CM_ "AUTOGENERATED FILE, DO NOT EDIT"

CM_ "toyota_auris_2014_pt.dbc starts here"
VERSION ""

NS_ :

BS_:

BU_: XXX DSU HCU EPS IPAS CGW SCM

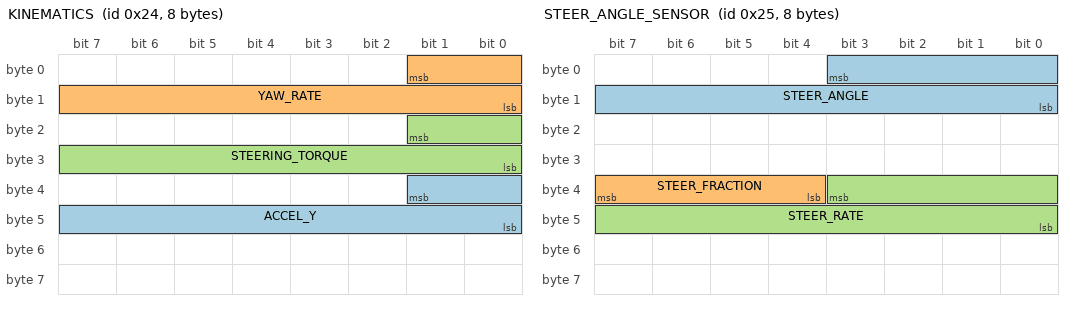
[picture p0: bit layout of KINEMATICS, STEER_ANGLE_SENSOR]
BO_ 36 KINEMATICS: 8 XXX
 SG_ ACCEL_Y : 33|10@0+ (0.03589,-18.375) [0|65535] "m/s^2" XXX
 SG_ YAW_RATE : 1|10@0+ (0.244,-125) [0|65535] "deg/sec" XXX
 SG_ STEERING_TORQUE : 17|10@0+ (1,-512) [0|65535] "" XXX

BO_ 37 STEER_ANGLE_SENSOR: 8 XXX
 SG_ STEER_ANGLE : 3|12@0- (1.5,0) [-500|500] "deg" XXX
 SG_ STEER_FRACTION : 39|4@0- (0.1,0) [-0.7|0.7] "deg" XXX
 SG_ STEER_RATE : 35|12@0- (1,0) [-2000|2000] "deg/s" XXX

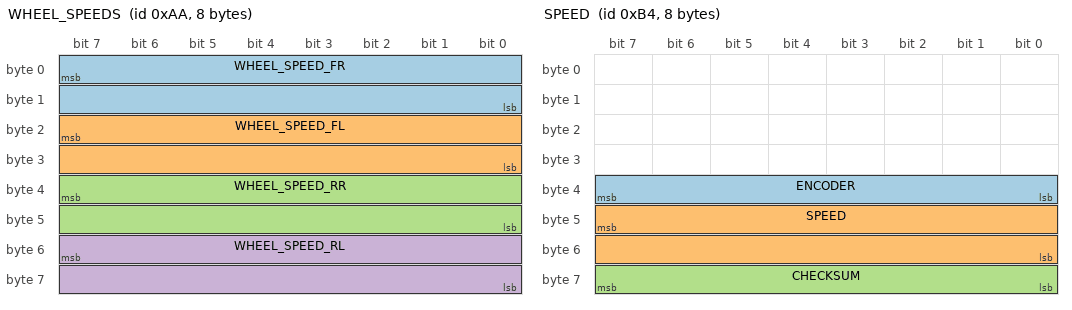
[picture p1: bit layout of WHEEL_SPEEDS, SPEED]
BO_ 170 WHEEL_SPEEDS: 8 XXX
 SG_ WHEEL_SPEED_FR : 7|16@0+ (0.01,-67.67) [0|250] "kph" XXX
 SG_ WHEEL_SPEED_FL : 23|16@0+ (0.01,-67.67) [0|250] "kph" XXX
 SG_ WHEEL_SPEED_RR : 39|16@0+ (0.01,-67.67) [0|250] "kph" XXX
 SG_ WHEEL_SPEED_RL : 55|16@0+ (0.01,-67.67) [0|250] "kph" XXX

BO_ 180 SPEED: 8 XXX
 SG_ ENCODER : 39|8@0+ (1,0) [0|255] "" XXX
 SG_ SPEED : 47|16@0+ (0.01,0) [0|250] "kph" XXX
 SG_ CHECKSUM : 63|8@0+ (1,0) [0|255] "" XXX

BO_ 548 BRAKE: 8 XXX
 SG_ BRAKE_PRESSED : 5|1@0+ (1,0) [0|1] "" XXX
 SG_ BRAKE_AMOUNT : 47|8@0+ (1,0) [0|255] "" XXX

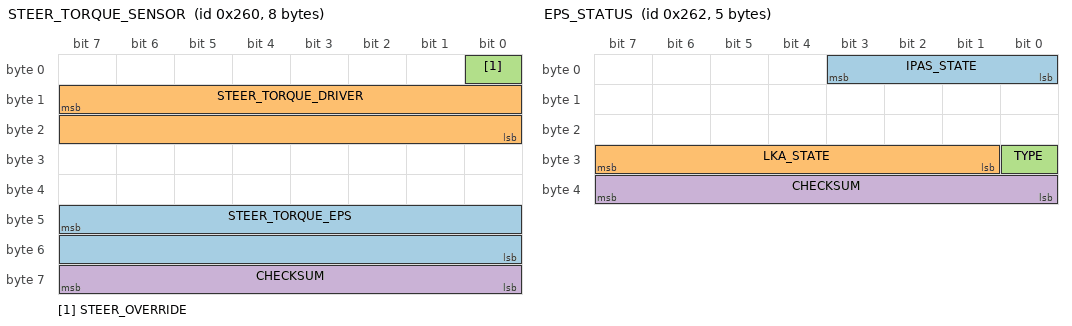
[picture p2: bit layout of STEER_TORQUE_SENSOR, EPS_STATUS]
BO_ 608 STEER_TORQUE_SENSOR: 8 XXX
 SG_ STEER_TORQUE_EPS : 47|16@0- (1.0,0) [-20000|20000] "" XXX
 SG_ STEER_TORQUE_DRIVER : 15|16@0- (1,0) [-32768|32767] "" XXX
 SG_ STEER_OVERRIDE : 0|1@0+ (1,0) [0|1] "" XXX
 SG_ CHECKSUM : 63|8@0+ (1,0) [0|255] "" XXX

BO_ 610 EPS_STATUS: 5 EPS
 SG_ IPAS_STATE : 3|4@0+ (1,0) [0|15] "" XXX
 SG_ LKA_STATE : 31|7@0+ (1,0) [0|127] "" XXX
 SG_ TYPE : 24|1@0+ (1,0) [0|1] "" XXX
 SG_ CHECKSUM : 39|8@0+ (1,0) [0|255] "" XXX

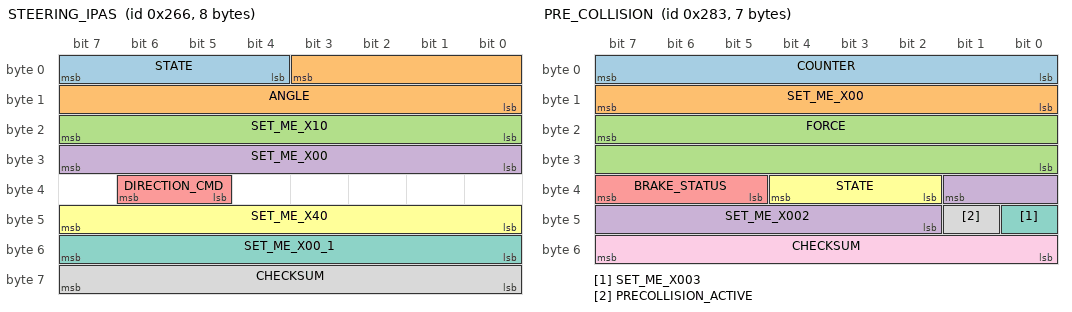
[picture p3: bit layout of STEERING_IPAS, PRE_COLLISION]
BO_ 614 STEERING_IPAS: 8 IPAS
 SG_ STATE : 7|4@0+ (1,0) [0|15] "" XXX
 SG_ ANGLE : 3|12@0- (1.5,0) [-510|510] "deg" XXX
 SG_ SET_ME_X10 : 23|8@0+ (1,0) [0|255] "" XXX
 SG_ SET_ME_X00 : 31|8@0+ (1,0) [0|255] "" XXX
 SG_ DIRECTION_CMD : 38|2@0+ (1,0) [0|3] "" XXX
 SG_ SET_ME_X40 : 47|8@0+ (1,0) [0|255] "" XXX
 SG_ SET_ME_X00_1 : 55|8@0+ (1,0) [0|255] "" XXX
 SG_ CHECKSUM : 63|8@0+ (1,0) [0|255] "" XXX

BO_ 643 PRE_COLLISION: 7 DSU
 SG_ COUNTER : 7|8@0+ (1,0) [0|255] "" XXX
 SG_ SET_ME_X00 : 15|8@0+ (1,0) [0|255] "" XXX
 SG_ FORCE : 23|16@0- (2,0) [0|255] "N" XXX
 SG_ SET_ME_X002 : 33|8@0+ (1,0) [0|3] "" XXX
 SG_ BRAKE_STATUS : 39|3@0+ (1,0) [0|255] "" XXX
 SG_ STATE : 36|3@0+ (1,0) [0|255] "" XXX
 SG_ SET_ME_X003 : 40|1@0+ (1,0) [0|1] "" XXX
 SG_ PRECOLLISION_ACTIVE : 41|1@0+ (1,0) [0|255] "" XXX
 SG_ CHECKSUM : 55|8@0+ (1,0) [0|255] "" XXX

BO_ 836 PRE_COLLISION_2: 8 DSU
 SG_ CHECKSUM : 63|8@0+ (1,0) [0|0] "" XXX

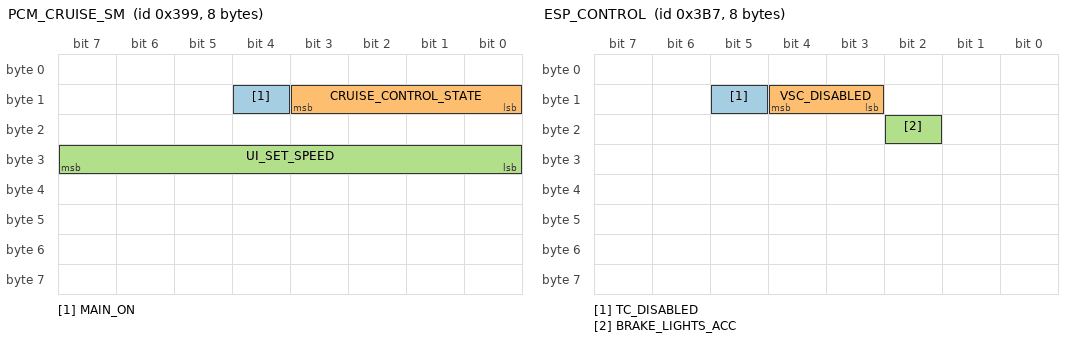
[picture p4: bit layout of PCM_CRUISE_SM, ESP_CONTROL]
BO_ 921 PCM_CRUISE_SM: 8 XXX
 SG_ MAIN_ON : 12|1@0+ (1,0) [0|1] "" XXX
 SG_ CRUISE_CONTROL_STATE : 11|4@0+ (1,0) [0|15] "" XXX
 SG_ UI_SET_SPEED : 31|8@0+ (1,0) [0|255] "" XXX

BO_ 951 ESP_CONTROL: 8 ESP
 SG_ TC_DISABLED : 13|1@0+ (1,0) [0|1] "" XXX
 SG_ VSC_DISABLED : 12|2@0+ (1,0) [0|1] "" XXX
 SG_ BRAKE_LIGHTS_ACC : 18|1@0+ (1,0) [0|1] "" XXX

BO_ 956 GEAR_PACKET: 8 XXX
 SG_ GEAR : 13|6@0+ (1,0) [0|63] "" XXX
 SG_ SPORT_ON : 3|1@0+ (1,0) [0|1] "" XXX

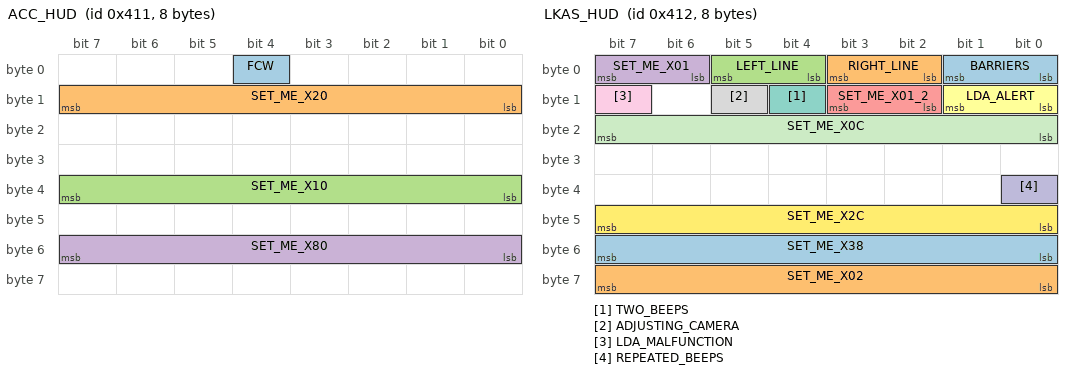
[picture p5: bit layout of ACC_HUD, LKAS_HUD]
BO_ 1041 ACC_HUD: 8 DSU
 SG_ FCW : 4|1@0+ (1,0) [0|1] "" XXX
 SG_ SET_ME_X20 : 15|8@0+ (1,0) [0|1] "" XXX
 SG_ SET_ME_X10 : 39|8@0+ (1,0) [0|1] "" XXX
 SG_ SET_ME_X80 : 55|8@0+ (1,0) [0|1] "" XXX

BO_ 1042 LKAS_HUD: 8 XXX
 SG_ BARRIERS : 1|2@0+ (1,0) [0|3] "" XXX
 SG_ RIGHT_LINE : 3|2@0+ (1,0) [0|3] "" XXX
 SG_ LEFT_LINE : 5|2@0+ (1,0) [0|3] "" XXX
 SG_ SET_ME_X01 : 7|2@0+ (1,0) [0|3] "" XXX
 SG_ SET_ME_X01_2 : 11|2@0+ (1,0) [0|3] "" XXX
 SG_ LDA_ALERT : 9|2@0+ (1,0) [0|3] "" XXX
 SG_ TWO_BEEPS : 12|1@0+ (1,0) [0|1] "" XXX
 SG_ ADJUSTING_CAMERA : 13|1@0+ (1,0) [0|1] "" XXX
 SG_ LDA_MALFUNCTION : 15|1@0+ (1,0) [0|1] "" XXX
 SG_ REPEATED_BEEPS : 32|1@0+ (1,0) [0|1] "" XXX
 SG_ SET_ME_X0C : 23|8@0+ (1,0) [0|1] "" XXX
 SG_ SET_ME_X2C : 47|8@0+ (1,0) [0|1] "" XXX
 SG_ SET_ME_X38 : 55|8@0+ (1,0) [0|1] "" XXX
 SG_ SET_ME_X02 : 63|8@0+ (1,0) [0|1] "" XXX

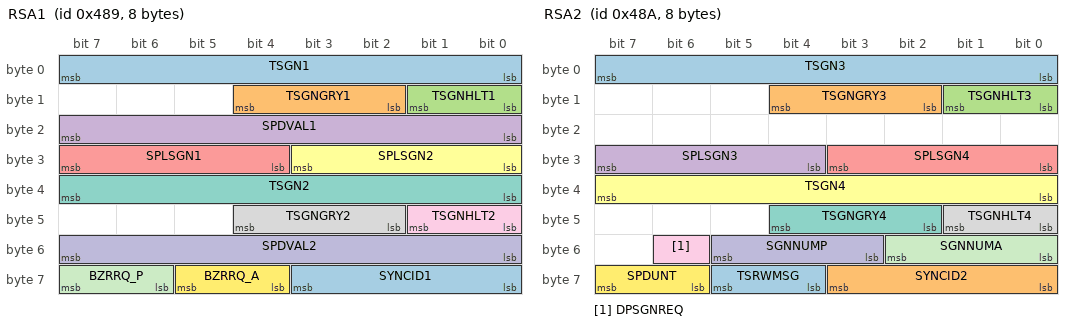
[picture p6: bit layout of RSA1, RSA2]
BO_ 1161 RSA1: 8 FCM
 SG_ TSGN1 : 7|8@0+ (1,0) [0|0] "" XXX
 SG_ TSGNGRY1 : 12|3@0+ (1,0) [0|0] "" XXX
 SG_ TSGNHLT1 : 9|2@0+ (1,0) [0|0] "" XXX
 SG_ SPDVAL1 : 23|8@0+ (1,0) [0|0] "kph" XXX
 SG_ SPLSGN1 : 31|4@0+ (1,0) [0|0] "" XXX
 SG_ SPLSGN2 : 27|4@0+ (1,0) [0|0] "" XXX
 SG_ TSGN2 : 39|8@0+ (1,0) [0|0] "" XXX
 SG_ TSGNGRY2 : 44|3@0+ (1,0) [0|0] "" XXX
 SG_ TSGNHLT2 : 41|2@0+ (1,0) [0|0] "" XXX
 SG_ SPDVAL2 : 55|8@0+ (1,0) [0|0] "" XXX
 SG_ BZRRQ_P : 63|2@0+ (1,0) [0|0] "" XXX
 SG_ BZRRQ_A : 61|2@0+ (1,0) [0|0] "" XXX
 SG_ SYNCID1 : 59|4@0+ (1,0) [0|0] "" XXX

BO_ 1162 RSA2: 8 FCM
 SG_ TSGN3 : 7|8@0+ (1,0) [0|0] "" XXX
 SG_ TSGNGRY3 : 12|3@0+ (1,0) [0|0] "" XXX
 SG_ TSGNHLT3 : 9|2@0+ (1,0) [0|0] "" XXX
 SG_ SPLSGN3 : 31|4@0+ (1,0) [0|0] "" XXX
 SG_ SPLSGN4 : 27|4@0+ (1,0) [0|0] "" XXX
 SG_ TSGN4 : 39|8@0+ (1,0) [0|0] "" XXX
 SG_ TSGNGRY4 : 44|3@0+ (1,0) [0|0] "" XXX
 SG_ TSGNHLT4 : 41|2@0+ (1,0) [0|0] "" XXX
 SG_ DPSGNREQ : 54|1@0+ (1,0) [0|0] "" XXX
 SG_ SGNNUMP : 53|3@0+ (1,0) [0|0] "" XXX
 SG_ SGNNUMA : 50|3@0+ (1,0) [0|0] "" XXX
 SG_ SPDUNT : 63|2@0+ (1,0) [0|0] "" XXX
 SG_ TSRWMSG : 61|2@0+ (1,0) [0|0] "" XXX
 SG_ SYNCID2 : 59|4@0+ (1,0) [0|0] "" XXX

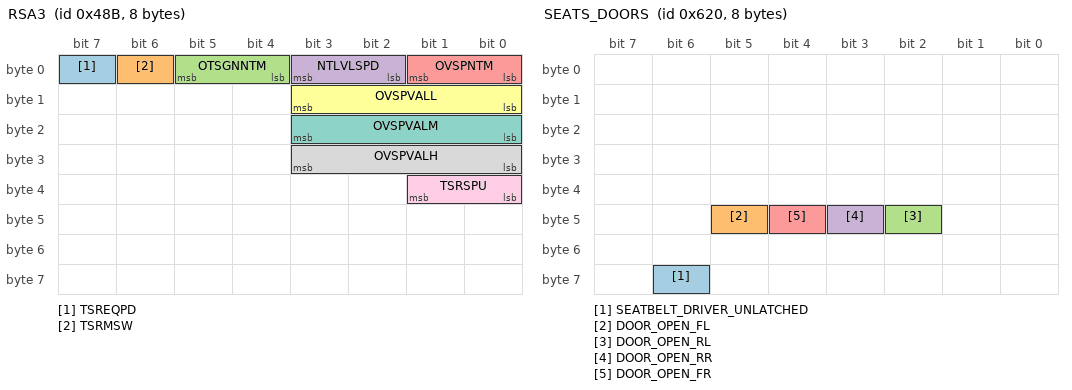
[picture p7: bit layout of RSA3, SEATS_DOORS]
BO_ 1163 RSA3: 8 FCM
 SG_ TSREQPD : 7|1@0+ (1,0) [0|0] "" XXX
 SG_ TSRMSW : 6|1@0+ (1,0) [0|0] "" XXX
 SG_ OTSGNNTM : 5|2@0+ (1,0) [0|0] "" XXX
 SG_ NTLVLSPD : 3|2@0+ (1,0) [0|0] "" XXX
 SG_ OVSPNTM : 1|2@0+ (1,0) [0|0] "" XXX
 SG_ OVSPVALL : 11|4@0+ (1,-5) [0|0] "" XXX
 SG_ OVSPVALM : 19|4@0+ (1,-5) [0|0] "" XXX
 SG_ OVSPVALH : 27|4@0+ (1,-5) [0|0] "" XXX
 SG_ TSRSPU : 33|2@0+ (1,0) [0|0] "" XXX

BO_ 1553 UI_SETTING: 8 XXX
 SG_ UNITS : 26|2@0+ (1,0) [0|3] "" XXX

BO_ 1556 STEERING_LEVERS: 8 XXX
 SG_ TURN_SIGNALS : 29|2@0+ (1,0) [0|3] "" XXX

BO_ 1568 SEATS_DOORS: 8 XXX
 SG_ SEATBELT_DRIVER_UNLATCHED : 62|1@0+ (1,0) [0|1] "" XXX
 SG_ DOOR_OPEN_FL : 45|1@0+ (1,0) [0|1] "" XXX
 SG_ DOOR_OPEN_RL : 42|1@0+ (1,0) [0|1] "" XXX
 SG_ DOOR_OPEN_RR : 43|1@0+ (1,0) [0|1] "" XXX
 SG_ DOOR_OPEN_FR : 44|1@0+ (1,0) [0|1] "" XXX

BO_ 1570 LIGHT_STALK: 8 SCM
 SG_ AUTO_HIGH_BEAM : 37|1@0+ (1,0) [0|1] "" XXX

CM_ SG_ 36 ACCEL_Y "does not seems to be Y accel, TBD";
CM_ SG_ 36 YAW_RATE "seems true";
CM_ SG_ 36 STEERING_TORQUE "definitely not the steering torque, TBD";
CM_ SG_ 37 STEER_ANGLE "positive is left, negative is right";
CM_ SG_ 37 STEER_FRACTION "1/15th of the signal STEER_ANGLE, which is 1.5 deg; note that 0x8 is never set";
CM_ SG_ 37 STEER_RATE "factor is tbd";
CM_ SG_ 608 STEER_TORQUE_DRIVER "driver torque";
CM_ SG_ 608 STEER_OVERRIDE "set when driver torque exceeds a certain value";
CM_ SG_ 610 LKA_STATE "0 value, not in range, TBD";
CM_ SG_ 610 TYPE "seems 1 on Corolla, 0 on all others";
CM_ SG_ 614 ANGLE "set to measured angle when ipas control isn't active";
CM_ SG_ 643 COUNTER "only used on cars that use this msg for cruise control";
CM_ SG_ 643 BRAKE_STATUS "only used on cars that use this msg for cruise control";
CM_ SG_ 643 PRECOLLISION_ACTIVE "set 0.5s before any braking";
CM_ SG_ 921 UI_SET_SPEED "set speed shown in UI with user set unit";
CM_ SG_ 951 BRAKE_LIGHTS_ACC "brake lights when ACC commands decel";
CM_ SG_ 1042 SET_ME_1 "unclear what this is, but it's always 1 in drive traces";
CM_ SG_ 1042 REPEATED_BEEPS "recommended for fcw and other important alerts";
CM_ SG_ 1161 SPDVAL1 "Numbers 0-199 is displayed, 200-254 displays circle without number and 255 is for no limit.";
CM_ SG_ 1161 SYNCID1 "counter from 1 to f at 1 Hz";
CM_ SG_ 1161 SPDVAL2 "conditional speed value 70"
CM_ SG_ 1162 SGNNUMP "1 if SPDVAL1 is set, otherwise 0";
CM_ SG_ 1162 SYNCID2 "counter from 1 to f at 1 Hz";
CM_ SG_ 1163 TSREQPD "always 1";
CM_ SG_ 1163 TSRMSW "always 1";
CM_ SG_ 1163 OTSGNNTM "always 3";
CM_ SG_ 1163 NTLVLSPD "always 3";
CM_ SG_ 1163 OVSPNTM "always 3";
CM_ SG_ 1163 OVSPVALL "-5 at start then 2 after 2 seconds";
CM_ SG_ 1163 OVSPVALM "-5 at start then 5 after 2 seconds";
CM_ SG_ 1163 OVSPVALH "-5 at start then 10 after 2 seconds";
CM_ SG_ 1163 TSRSPU "always 1";

VAL_ 548 BRAKE_PRESSED 0 "not pressed" 1 "pressed";
VAL_ 610 IPAS_STATE 5 "override" 3 "enabled" 1 "disabled";
VAL_ 610 LKA_STATE 25 "temporary_fault" 9 "temporary_fault2" 5 "active" 1 "standby";
VAL_ 614 STATE 3 "enabled" 1 "disabled";
VAL_ 614 DIRECTION_CMD 3 "right" 2 "center" 1 "left";
VAL_ 643 STATE 0 "normal" 1 "adaptive_cruise_control" 3 "emergency_braking";
VAL_ 921 CRUISE_CONTROL_STATE 0 "disabled" 2 "enabled";
VAL_ 956 GEAR 0 "D" 1 "S" 8 "N" 16 "R" 32 "P";
VAL_ 1042 LDA_ALERT 3 "hold with continuous beep" 2 "LDA unavailable" 1 "hold" 0 "none";
VAL_ 1042 BARRIERS 3 "both" 2 "right" 1 "left" 0 "none";
VAL_ 1042 RIGHT_LINE 3 "orange" 2 "faded" 1 "solid" 0 "none";
VAL_ 1042 LEFT_LINE 3 "orange" 2 "faded" 1 "solid" 0 "none";
VAL_ 1553 UNITS 1 "km" 2 "miles";
VAL_ 1556 TURN_SIGNALS 3 "none" 2 "right" 1 "left";
VAL_ 1161 TSGN1 1 "speed sign" 0 "none";
VAL_ 1161 TSGN2 1 "speed sign" 0 "none";
VAL_ 1161 SPLSGN2 15 "conditional blank" 4 "wet road" 5 "rain" 0 "none";
VAL_ 1162 TSGN3 0 "none" 1 "speed sign" 2 "0 unlimited" 7 "unlimited" 16 "highway" 17 "no highway" 18 "motorway" 19 "no motorway" 20 "in city" 21 "outside city" 22 "pedestrian area" 23 "no pedestrian area" 65 "no overtaking left" 66 "no overtaking right" 67 "overtaking allowed again" 129 "no entry";
VAL_ 1162 SPLSGN3 15 "conditional blank" 4 "wet road" 5 "rain" 0 "none";
